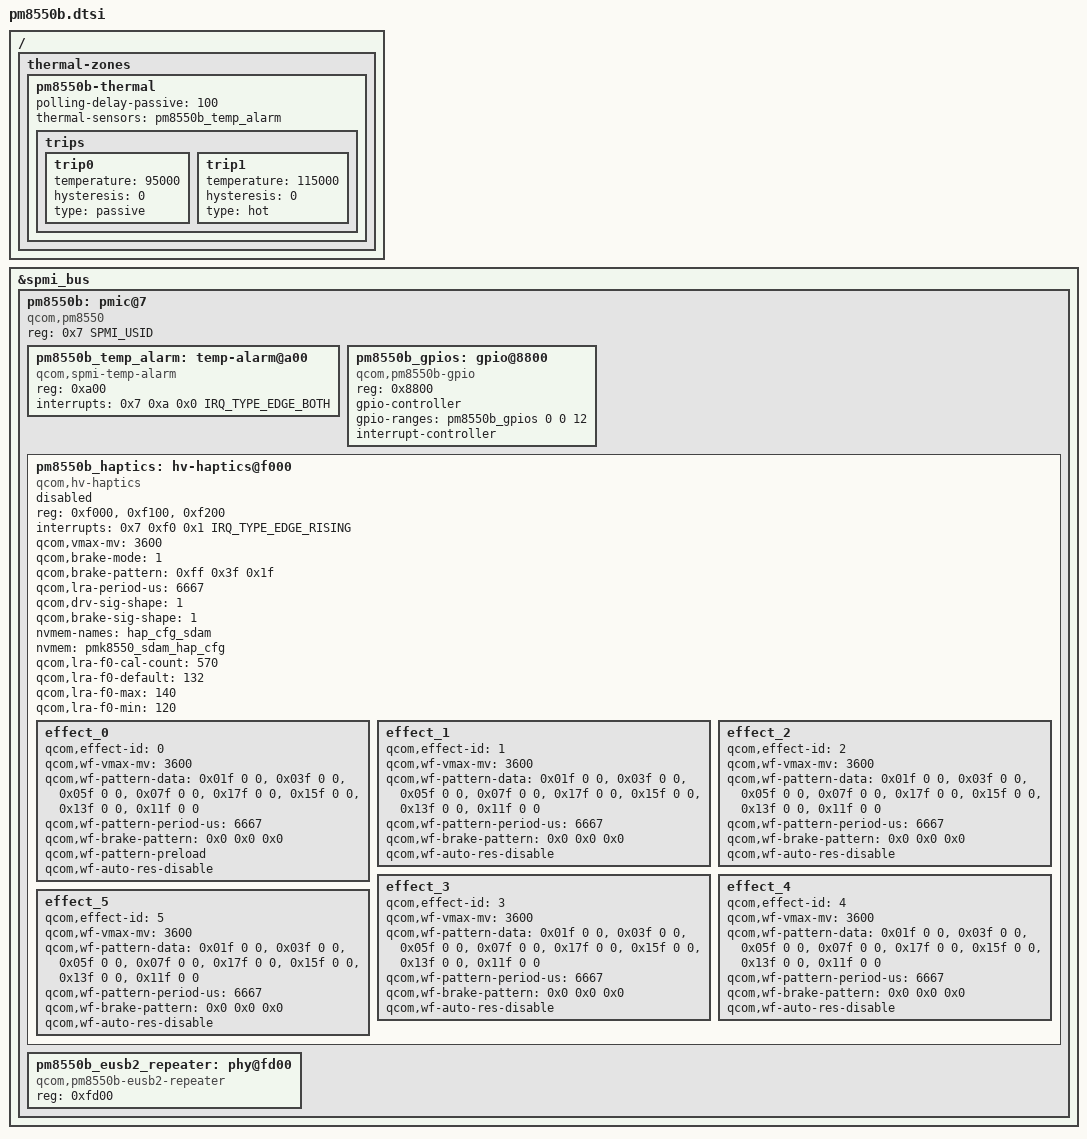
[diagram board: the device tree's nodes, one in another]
// SPDX-License-Identifier: BSD-3-Clause
/*
 * Copyright (c) 2022, Linaro Limited
 */

#include <dt-bindings/interrupt-controller/irq.h>
#include <dt-bindings/spmi/spmi.h>

/ {
	thermal-zones {
		pm8550b-thermal {
			polling-delay-passive = <100>;

			thermal-sensors = <&pm8550b_temp_alarm>;

			trips {
				trip0 {
					temperature = <95000>;
					hysteresis = <0>;
					type = "passive";
				};

				trip1 {
					temperature = <115000>;
					hysteresis = <0>;
					type = "hot";
				};
			};
		};
	};
};


&spmi_bus {
	pm8550b: pmic@7 {
		compatible = "qcom,pm8550", "qcom,spmi-pmic";
		reg = <0x7 SPMI_USID>;
		#address-cells = <1>;
		#size-cells = <0>;

		pm8550b_temp_alarm: temp-alarm@a00 {
			compatible = "qcom,spmi-temp-alarm";
			reg = <0xa00>;
			interrupts = <0x7 0xa 0x0 IRQ_TYPE_EDGE_BOTH>;
			#thermal-sensor-cells = <0>;
		};

		pm8550b_gpios: gpio@8800 {
			compatible = "qcom,pm8550b-gpio", "qcom,spmi-gpio";
			reg = <0x8800>;
			gpio-controller;
			gpio-ranges = <&pm8550b_gpios 0 0 12>;
			#gpio-cells = <2>;
			interrupt-controller;
			#interrupt-cells = <2>;
		};

		pm8550b_haptics: hv-haptics@f000 {
			compatible = "qcom,hv-haptics";
			reg = <0xf000>, <0xf100>, <0xf200>;
			interrupts = <0x7 0xf0 0x1 IRQ_TYPE_EDGE_RISING>;
			interrupt-names = "fifo-empty";
			qcom,vmax-mv = <3600>;
			qcom,brake-mode = <1>;
			qcom,brake-pattern = /bits/ 8 <0xff 0x3f 0x1f>;
			qcom,lra-period-us = <6667>;
			qcom,drv-sig-shape = <1>;
			qcom,brake-sig-shape = <1>;
			status = "disabled";
			nvmem-names = "hap_cfg_sdam";
			nvmem = <&pmk8550_sdam_hap_cfg>;
			qcom,lra-f0-cal-count = <570>;
			qcom,lra-f0-default = <132>;
			qcom,lra-f0-max = <140>;
			qcom,lra-f0-min = <120>;

			effect_0 {
				/* CLICK */
				qcom,effect-id = <0>;
				qcom,wf-vmax-mv = <3600>;
				qcom,wf-pattern-data =  <0x01f  0  0>,
							<0x03f  0  0>,
							<0x05f  0  0>,
							<0x07f  0  0>,
							<0x17f  0  0>,
							<0x15f  0  0>,
							<0x13f  0  0>,
							<0x11f  0  0>;
				qcom,wf-pattern-period-us = <6667>;
				qcom,wf-brake-pattern = /bits/ 8 <0x0 0x0 0x0>;
				qcom,wf-pattern-preload;
				qcom,wf-auto-res-disable;
			};

			effect_1 {
				/* DOUBLE_CLICK */
				qcom,effect-id = <1>;
				qcom,wf-vmax-mv = <3600>;
				qcom,wf-pattern-data =  <0x01f  0  0>,
							<0x03f  0  0>,
							<0x05f  0  0>,
							<0x07f  0  0>,
							<0x17f  0  0>,
							<0x15f  0  0>,
							<0x13f  0  0>,
							<0x11f  0  0>;
				qcom,wf-pattern-period-us = <6667>;
				qcom,wf-brake-pattern = /bits/ 8 <0x0 0x0 0x0>;
				qcom,wf-auto-res-disable;
			};

			effect_2 {
				/* TICK */
				qcom,effect-id = <2>;
				qcom,wf-vmax-mv = <3600>;
				qcom,wf-pattern-data =  <0x01f  0  0>,
							<0x03f  0  0>,
							<0x05f  0  0>,
							<0x07f  0  0>,
							<0x17f  0  0>,
							<0x15f  0  0>,
							<0x13f  0  0>,
							<0x11f  0  0>;
				qcom,wf-pattern-period-us = <6667>;
				qcom,wf-brake-pattern = /bits/ 8 <0x0 0x0 0x0>;
				qcom,wf-auto-res-disable;
			};

			effect_3 {
				/* THUD */
				qcom,effect-id = <3>;
				qcom,wf-vmax-mv = <3600>;
				qcom,wf-pattern-data =  <0x01f  0  0>,
							<0x03f  0  0>,
							<0x05f  0  0>,
							<0x07f  0  0>,
							<0x17f  0  0>,
							<0x15f  0  0>,
							<0x13f  0  0>,
							<0x11f  0  0>;
				qcom,wf-pattern-period-us = <6667>;
				qcom,wf-brake-pattern = /bits/ 8 <0x0 0x0 0x0>;
				qcom,wf-auto-res-disable;
			};

			effect_4 {
				/* POP */
				qcom,effect-id = <4>;
				qcom,wf-vmax-mv = <3600>;
				qcom,wf-pattern-data =  <0x01f  0  0>,
							<0x03f  0  0>,
							<0x05f  0  0>,
							<0x07f  0  0>,
							<0x17f  0  0>,
							<0x15f  0  0>,
							<0x13f  0  0>,
							<0x11f  0  0>;
				qcom,wf-pattern-period-us = <6667>;
				qcom,wf-brake-pattern = /bits/ 8 <0x0 0x0 0x0>;
				qcom,wf-auto-res-disable;
			};

			effect_5 {
				/* HEAVY CLICK */
				qcom,effect-id = <5>;
				qcom,wf-vmax-mv = <3600>;
				qcom,wf-pattern-data =  <0x01f  0  0>,
							<0x03f  0  0>,
							<0x05f  0  0>,
							<0x07f  0  0>,
							<0x17f  0  0>,
							<0x15f  0  0>,
							<0x13f  0  0>,
							<0x11f  0  0>;
				qcom,wf-pattern-period-us = <6667>;
				qcom,wf-brake-pattern = /bits/ 8 <0x0 0x0 0x0>;
				qcom,wf-auto-res-disable;
			};
		};

		pm8550b_eusb2_repeater: phy@fd00 {
			compatible = "qcom,pm8550b-eusb2-repeater";
			reg = <0xfd00>;
			#phy-cells = <0>;
		};
	};
};
